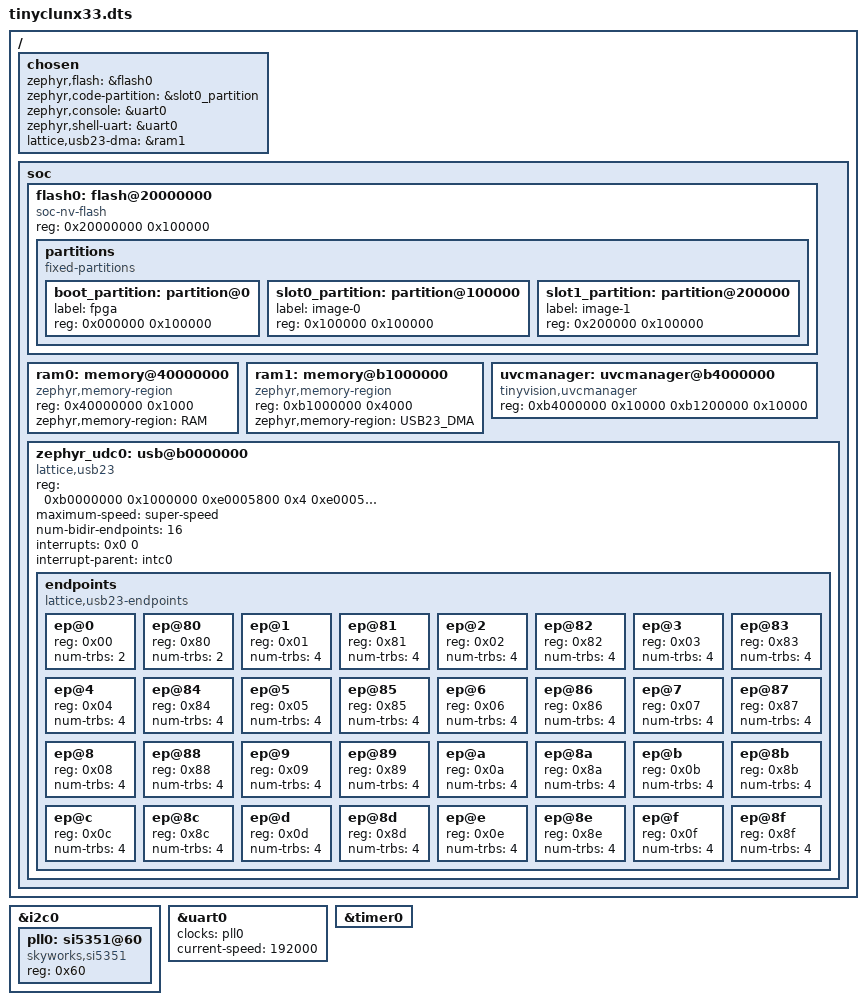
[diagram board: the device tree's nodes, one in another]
/*
 * Copyright (c) 2024 tinyVision.ai Inc.
 *
 * SPDX-License-Identifier: Apache-2.0
 */

/dts-v1/;
#include <riscv32-litex-vexriscv.dtsi>

/ {
	chosen {
		zephyr,flash = &flash0;
		zephyr,code-partition = &slot0_partition;
		zephyr,console = &uart0;
		zephyr,shell-uart = &uart0;
		lattice,usb23-dma = &ram1;
	};

	soc {
		flash0: flash@20000000 {
			compatible = "soc-nv-flash";

			reg = <0x20000000 0x100000>;
			status = "okay";

			partitions {
				compatible = "fixed-partitions";
				#address-cells = <1>;
				#size-cells = <1>;

				boot_partition: partition@0 {
					label = "fpga";
					reg = <0x000000 0x100000>;
				};

				slot0_partition: partition@100000 {
					label = "image-0";
					reg = <0x100000 0x100000>;
				};

				slot1_partition: partition@200000 {
					label = "image-1";
					reg = <0x200000 0x100000>;
				};
			};
		};

		ram0: memory@40000000 {
			compatible = "zephyr,memory-region";
			device_type = "memory";
			reg = <0x40000000 0x1000>;
			zephyr,memory-region = "RAM";
		};

		ram1: memory@b1000000 {
			compatible = "zephyr,memory-region";
			device_type = "memory";
			reg = <0xb1000000 0x4000>;
			zephyr,memory-region = "USB23_DMA";
		};

		uvcmanager: uvcmanager@b4000000 {
			compatible = "tinyvision,uvcmanager";
			status = "okay";
			reg = <	0xb4000000 0x10000
				0xb1200000 0x10000>;
			reg-names =
				"base",
				"fifo";
		};

		zephyr_udc0: usb@b0000000 {
			compatible = "lattice,usb23";
			reg = <	0xb0000000 0x1000000
				0xe0005800 0x4
				0xe0005804 0x4
				0xe0005808 0x4>;
			reg-names =
				"base",
				"ev_status",
				"ev_pending",
				"ev_enable";
			maximum-speed = "super-speed";
			num-bidir-endpoints = <16>;
			interrupts = <0x0 0>;
			interrupt-names = "usb";
			interrupt-parent = <&intc0>;
			status = "okay";

			endpoints {
				compatible = "lattice,usb23-endpoints";
				#address-cells = <1>;
				#size-cells = <0>;

				ep@0 {
					reg = <0x00>;
					num-trbs = <2>;
				};

				ep@80 {
					reg = <0x80>;
					num-trbs = <2>;
				};

				ep@1 {
					reg = <0x01>;
					num-trbs = <4>;
				};

				ep@81 {
					reg = <0x81>;
					num-trbs = <4>;
				};

				ep@2 {
					reg = <0x02>;
					num-trbs = <4>;
				};

				ep@82 {
					reg = <0x82>;
					num-trbs = <4>;
				};

				ep@3 {
					reg = <0x03>;
					num-trbs = <4>;
				};

				ep@83 {
					reg = <0x83>;
					num-trbs = <4>;
				};

				ep@4 {
					reg = <0x04>;
					num-trbs = <4>;
				};

				ep@84 {
					reg = <0x84>;
					num-trbs = <4>;
				};

				ep@5 {
					reg = <0x05>;
					num-trbs = <4>;
				};

				ep@85 {
					reg = <0x85>;
					num-trbs = <4>;
				};

				ep@6 {
					reg = <0x06>;
					num-trbs = <4>;
				};

				ep@86 {
					reg = <0x86>;
					num-trbs = <4>;
				};

				ep@7 {
					reg = <0x07>;
					num-trbs = <4>;
				};

				ep@87 {
					reg = <0x87>;
					num-trbs = <4>;
				};

				ep@8 {
					reg = <0x08>;
					num-trbs = <4>;
				};

				ep@88 {
					reg = <0x88>;
					num-trbs = <4>;
				};

				ep@9 {
					reg = <0x09>;
					num-trbs = <4>;
				};

				ep@89 {
					reg = <0x89>;
					num-trbs = <4>;
				};

				ep@a {
					reg = <0x0a>;
					num-trbs = <4>;
				};

				ep@8a {
					reg = <0x8a>;
					num-trbs = <4>;
				};

				ep@b {
					reg = <0x0b>;
					num-trbs = <4>;
				};

				ep@8b {
					reg = <0x8b>;
					num-trbs = <4>;
				};

				ep@c {
					reg = <0x0c>;
					num-trbs = <4>;
				};

				ep@8c {
					reg = <0x8c>;
					num-trbs = <4>;
				};

				ep@d {
					reg = <0x0d>;
					num-trbs = <4>;
				};

				ep@8d {
					reg = <0x8d>;
					num-trbs = <4>;
				};

				ep@e {
					reg = <0x0e>;
					num-trbs = <4>;
				};

				ep@8e {
					reg = <0x8e>;
					num-trbs = <4>;
				};

				ep@f {
					reg = <0x0f>;
					num-trbs = <4>;
				};

				ep@8f {
					reg = <0x8f>;
					num-trbs = <4>;
				};
			};
		};
	};
};

&i2c0 {
	status = "okay";

	pll0: si5351@60 {
		reg = <0x60>;
		compatible = "skyworks,si5351";
		#clock-cells = <0>;
		status = "okay";
	};
};

&uart0 {
	/* Turned off to let the board start when ther is no PLL */
	clocks = <&pll0>;

	/* Value for RTL Reference Design v0.5 */
	current-speed = <192000>;

	status = "okay";
};

&timer0 {
	status = "okay";
};

#include "tinyclunx33_litex.dtsi"
